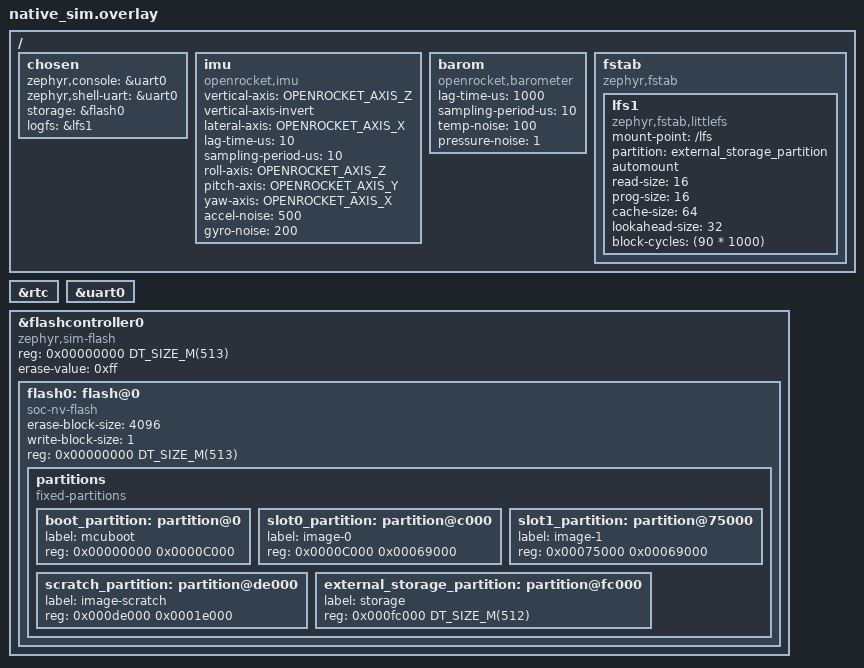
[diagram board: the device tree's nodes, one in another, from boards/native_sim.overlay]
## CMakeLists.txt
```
cmake_minimum_required(VERSION 3.20.0)

find_package(Zephyr REQUIRED HINTS $ENV{ZEPHYR_BASE})
project(sample_logging LANGUAGES C CXX)

FILE(GLOB app_sources src/*.cpp src/*.c)

#target_compile_options(app PRIVATE -Wno-unused-parameter -Wno-unused-function -Wno-ignored-qualifiers)
target_sources(app PRIVATE ${app_sources})
```

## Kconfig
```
# Copyright (c) 2021 Nordic Semiconductor ASA
# SPDX-License-Identifier: Apache-2.0
#
# This file is the application Kconfig entry point. All application Kconfig
# options can be defined here or included via other application Kconfig files.
# You can browse these options using the west targets menuconfig (terminal) or
# guiconfig (GUI).

menu "Zephyr"
source "Kconfig.zephyr"
endmenu


module = APP_PHASE_DETECT
module-str = APP_PHASE_DETECT
source "subsys/logging/Kconfig.template.log_config"
```

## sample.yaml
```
sample:
  description: phase-detection
  name: phase-detection
common:
  build_only: true
  platform_allow:
    - native_sim
tests:
  samples.phase_detection.default: {}
```

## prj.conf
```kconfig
# CPP
CONFIG_CPP=y
CONFIG_REQUIRES_FULL_LIBCPP=y
CONFIG_STD_CPP20=y
CONFIG_ASAN=y

CONFIG_F_CORE=y
CONFIG_F_CORE_SENSOR=y
CONFIG_F_CORE_OS=y
CONFIG_F_CORE_UTILS=y

CONFIG_SENSOR=y
CONFIG_SHELL=y
CONFIG_SENSOR_SHELL=y
CONFIG_FILE_SYSTEM_SHELL=y
CONFIG_HEAP_MEM_POOL_SIZE=4096
CONFIG_EVENTS=y


CONFIG_SERIAL=y
CONFIG_CBPRINTF_FP_SUPPORT=y
CONFIG_CONSOLE=y

CONFIG_LOG=y
CONFIG_LOG_MODE_IMMEDIATE=y
CONFIG_APP_PHASE_DETECT_LOG_LEVEL_DBG=y

# Flash chip is SPI
CONFIG_FLASH=y
# LittleFS requires a flash map device
CONFIG_FLASH_MAP=y
CONFIG_FLASH_PAGE_LAYOUT=y

# Use filesystem
CONFIG_FILE_SYSTEM=y
# Use LittleFS as the filesystem
CONFIG_FILE_SYSTEM_LITTLEFS=y
# LittleFS is mounted on a flash map device
CONFIG_FS_LITTLEFS_FMP_DEV=y 

# Flash chip is SPI
CONFIG_FLASH=y
# LittleFS requires a flash map device
CONFIG_FLASH_MAP=y
CONFIG_FLASH_PAGE_LAYOUT=y

# CONFIG_FUSE_FS_ACCESS=y
```

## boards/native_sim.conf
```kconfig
CONFIG_SYS_CLOCK_TICKS_PER_SEC=10000
CONFIG_UBSAN=y

CONFIG_OPENROCKET_SENSORS=y

CONFIG_OPENROCKET_NOISE=y
CONFIG_OPENROCKET_NOISE_SEED=0
CONFIG_TEST_RANDOM_GENERATOR=y
CONFIG_XOSHIRO_RANDOM_GENERATOR=y
CONFIG_TIMER_RANDOM_GENERATOR=y

CONFIG_OPENROCKET_DATA_FILE="../../../data/orksim_csv/omen.csv"
CONFIG_OPENROCKET_MS_BEFORE_LAUNCH=2000
CONFIG_OPENROCKET_SCALAR_TYPE_DOUBLE=y
CONFIG_OPENROCKET_EVENT_LOG=y

CONFIG_OPENROCKET_IMU=y
CONFIG_OPENROCKET_BAROMETER=y
```

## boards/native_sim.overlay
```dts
/ {
    chosen {
        zephyr,console = &uart0;
        zephyr,shell-uart = &uart0;

        storage = &flash0;
        logfs = &lfs1;
    };


    imu: imu {
        status = "okay";
        // broken;
        compatible = "openrocket,imu";
        vertical-axis = "OPENROCKET_AXIS_Z";
        vertical-axis-invert;
        lateral-axis = "OPENROCKET_AXIS_X";
        lag-time-us = <10>;
        sampling-period-us = <10>;

        roll-axis = "OPENROCKET_AXIS_Z";
        pitch-axis = "OPENROCKET_AXIS_Y";
        yaw-axis = "OPENROCKET_AXIS_X";

        accel-noise = <500>;
        gyro-noise = <200>;
    };

    barom: barom {
        status = "okay";
        compatible = "openrocket,barometer";
        lag-time-us = <1000>;
        sampling-period-us = <10>;
        temp-noise = <100>; // millicelsius
        pressure-noise = <1>; // kPa / 1000
    };

    fstab {
        compatible = "zephyr,fstab";
        lfs1: lfs1 {
            compatible = "zephyr,fstab,littlefs";
            mount-point = "/lfs";
            partition = <&external_storage_partition>;
            automount;

            // the binding reccomends defaults for these
            read-size = <16>;
            prog-size = <16>;
            cache-size = <64>; // may need to grow for optimization
            lookahead-size = <32>;
            block-cycles = <(90 * 1000)>;
            // the datasheet gives 100K P-E cycles
            // NOTE: this seems to default to 512 for the mounted filesystem
            // anyway
        };
    };

};
&rtc {
    status = "okay";
};
&uart0 {
    status = "okay";
};

&flashcontroller0 {
    status = "okay";
    compatible = "zephyr,sim-flash";
    reg = <0x00000000 DT_SIZE_M(513)>;

    #address-cells = <1>;
    #size-cells = <1>;
    erase-value = <0xff>;

    flash0: flash@0 {
        status = "okay";
        compatible = "soc-nv-flash";
        erase-block-size = <4096>;
        write-block-size = <1>;
        reg = <0x00000000 DT_SIZE_M(513)>; // builtin stuff + external flash simulation

        partitions {
            compatible = "fixed-partitions";
            #address-cells = <1>;
            #size-cells = <1>;

            boot_partition: partition@0 {
                label = "mcuboot";
                reg = <0x00000000 0x0000C000>;
            };
            slot0_partition: partition@c000 {
                label = "image-0";
                reg = <0x0000C000 0x00069000>;
            };
            slot1_partition: partition@75000 {
                label = "image-1";
                reg = <0x00075000 0x00069000>;
            };
            scratch_partition: partition@de000 {
                label = "image-scratch";
                reg = <0x000de000 0x0001e000>;
            };
            external_storage_partition: partition@fc000 {
                label = "storage";
                reg = <0x000fc000 DT_SIZE_M(512)>;
            };
        };
    };
};
```

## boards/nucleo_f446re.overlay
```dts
/ {
    chosen {
        zephyr,console = &usart2;
    };
    imu: imu {
        compatible = "openrocket,imu";
        vertical-axis = "OPENROCKET_AXIS_Z";
        vertical-axis-invert;
        lateral-axis = "OPENROCKET_AXIS_X";
        lag-time-us = <1000>;
        sampling-period-us = <10>;

        roll-axis = "OPENROCKET_AXIS_Z";
        pitch-axis = "OPENROCKET_AXIS_Y";
        yaw-axis = "OPENROCKET_AXIS_X";
    };

    barom: barom {
        status = "okay";
        compatible = "openrocket,barometer";
        lag-time-us = <1000>;
        sampling-period-us = <10>;

    };

    gnss: gnss{
        status = "okay";
        compatible = "openrocket,gnss";
        lag-time-us = <1000>;
        sampling-period-us = <(5*1000*1000)>;
        rtc = <&rtc>;
    };
};
```

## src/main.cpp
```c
// F-Core Includes
#include "f_core/os/flight_log.hpp"
#include "f_core/utils/debouncer.hpp"
#include "f_core/utils/linear_fit.hpp"
#include "flight.h"

#include <array>
#include <f_core/device/sensor/c_accelerometer.h>
#include <f_core/device/sensor/c_barometer.h>
#include <f_core/device/sensor/c_gyroscope.h>
#include <f_core/device/sensor/c_magnetometer.h>
#include <math.h>
// Zephyr Includes
#include <zephyr/device.h>
#include <zephyr/devicetree.h>
#include <zephyr/drivers/sensor.h>
#include <zephyr/kernel.h>
#include <zephyr/logging/log.h>
LOG_MODULE_REGISTER(main, CONFIG_APP_PHASE_DETECT_LOG_LEVEL);

K_TIMER_DEFINE(imu_timer, NULL, NULL);
K_TIMER_DEFINE(barom_timer, NULL, NULL);

void imu_thread_f(void *vp_controller, void *, void *) {
    Controller &controller = *(Controller *) vp_controller;

    // > 5G-ish for a quarter second
    constexpr uint32_t boost_time_ms = 250;
    constexpr double boost_threshold_mps2 = 50;

    // < 3.5G-ish for a quarter second
    // weird since this example is doing what grim did and doing it based on magnitude not a specific axis
    // Deceleration is still acceleration which is why we cant just say < 1G
    constexpr uint32_t coast_time_ms = 250;
    constexpr double coast_threshold_mps2 = 35;
    CDebouncer<ThresholdDirection::Over, double> boost_detector{boost_time_ms, boost_threshold_mps2};
    CDebouncer<ThresholdDirection::Under, double> coast_detector{coast_time_ms, coast_threshold_mps2};

    CAccelerometer acc(*DEVICE_DT_GET_ONE(openrocket_imu));
    if (!acc.IsReady()) {
        LOG_WRN("Accelerometer not ready");
    }
    controller.SubmitEvent(Sources::IMU1, Events::PadReady);
    controller.WaitUntilEvent(Events::PadReady);

    while (!controller.HasEventOccurred(Events::GroundHit)) {
        k_timer_status_sync(&imu_timer);
        uint32_t timestamp = k_uptime_get();

        if (!acc.UpdateSensorValue()) {
            LOG_ERR("Failure reading imu");
        }
        double x = acc.GetSensorValueDouble(SENSOR_CHAN_ACCEL_X);
        double y = acc.GetSensorValueDouble(SENSOR_CHAN_ACCEL_Y);
        double z = acc.GetSensorValueDouble(SENSOR_CHAN_ACCEL_Z);
        double mag = sqrt((x * x) + (y * y) + (z * z));

        // Boost Detecting
        if (!controller.HasEventOccurred(Events::Boost)) {
            boost_detector.Feed(timestamp, mag);
            coast_detector.Feed(timestamp, mag);
            if (boost_detector.Passed()) {
                controller.SubmitEvent(Sources::IMU1, Events::Boost);
            }
        } else if (!controller.HasEventOccurred(Events::Coast)) {
            coast_detector.Feed(timestamp, mag);
            if (coast_detector.Passed()) {
                controller.SubmitEvent(Sources::IMU1, Events::Coast);
            }
        }
    }
}

using SampleType = LinearFitSample<double>;
static constexpr std::size_t window_size = 10;
using SummerType = CRollingSum<SampleType, window_size>;

struct Line {
    double m;
    double b;
    constexpr bool operator==(const Line &rhs) const { return m == rhs.m && b == rhs.b; }
};

// Value returned when we don't have enough information to fit a line
constexpr Line bad_line{0, 0};

Line find_line(const SummerType &summer) {
    std::size_t N = summer.Size();
    SampleType E = summer.Sum();
    double denom = (N * E.xx - E.x * E.x);
    if (denom == 0) {
        // Would have divided by 0
        return bad_line;
    }
    double m = (N * E.xy - E.x * E.y) / denom;
    double b = (E.y - m * E.x) / N;
    return Line{m, b};
}

double rrc3_altitude_conversion_to_feet(double P_sta_kpa) {
    // Constants from https://www.weather.gov/media/epz/wxcalc/pressureAltitude.pdf
    static constexpr double standard_atmosphere_exponent = 0.190284;
    static constexpr double standard_atmosphere_factor = 145366.45;

    static constexpr double kpa_to_mbar = 10.0;
    static constexpr double sea_level_pressure_mbar = 1013.25;
    double P_sta_mbar = P_sta_kpa * kpa_to_mbar;

    return (1 - pow(P_sta_mbar / sea_level_pressure_mbar, standard_atmosphere_exponent)) * standard_atmosphere_factor;
}

using BoostDebouncerT = CDebouncer<ThresholdDirection::Over, double>;
using NoseoverDebouncerT = CDebouncer<ThresholdDirection::Under, double>;
using MainHeightDebouncerT = CDebouncer<ThresholdDirection::Under, double>;
using NoVelocityDebouncerT = CDebouncer<ThresholdDirection::Under, double>;

void barom_thread_f(void *vp_controller, void *, void *) {
    Controller &controller = *(Controller *) vp_controller;

    CBarometer barometer(*DEVICE_DT_GET_ONE(openrocket_barometer));
    if (!barometer.IsReady()) {
        LOG_WRN("Accelerometer not ready");
    }
    controller.SubmitEvent(Sources::Barom1, Events::PadReady);
    controller.WaitUntilEvent(Events::PadReady);

    // Measure
    barometer.UpdateSensorValue();
    double init_press_kpa = barometer.GetSensorValueDouble(SENSOR_CHAN_PRESS);
    double init_feet_asl = rrc3_altitude_conversion_to_feet(init_press_kpa);
    double max_feet_agl = 0;

    SummerType velocity_summer{SampleType{0, 0}};
    CMovingAverage<double, 100> ground_level_avger{init_feet_asl};

    // >5g for 2 seconds
    constexpr uint32_t boost_time_ms = 2000; // ms
    constexpr uint32_t boost_threshold = 5;  // ft/s
    BoostDebouncerT boost_debouncer{boost_time_ms, boost_threshold};

    // Under 0ft/s for 0.5 seconds
    constexpr uint32_t noseover_velocity_time_ms = 500;
    constexpr double noseover_velocity_threshold = 0.0;
    NoseoverDebouncerT noseover_debouncer{noseover_velocity_time_ms, noseover_velocity_threshold};

    // Under 500ft for 0.5 seconds
    constexpr uint32_t mainheight_time_ms = 500;
    constexpr double mainheight_threshold = 500.0;
    MainHeightDebouncerT mainheight_debouncer{mainheight_time_ms, mainheight_threshold};

    // under 10 ft/s for 10 seconds
    constexpr uint32_t no_vel_time_ms = 10 * 1000;
    constexpr double no_vel_threshold = 10.0;
    NoVelocityDebouncerT no_vel_debouncer{no_vel_time_ms, no_vel_threshold};

    while (!controller.HasEventOccurred(Events::GroundHit)) {
        k_timer_status_sync(&barom_timer);
        bool good = barometer.UpdateSensorValue();
        if (!good) {
            LOG_ERR("Failure reading barometer");
        }

        // Measure
        double press_kpa = barometer.GetSensorValueDouble(SENSOR_CHAN_PRESS);

        uint32_t time_ms = k_uptime_get();
        double time_s = (double) (time_ms) / 1000.0;

        // Calculate
        double feet = rrc3_altitude_conversion_to_feet(press_kpa);

        velocity_summer.Feed({time_s, feet});
        Line line = find_line(velocity_summer);

        // Not enough samples, don't check
        if (line == bad_line) {
            continue;
        }
        double velocity_ft_s = line.m;
        double feet_agl = feet - ground_level_avger.Avg();
        if (feet_agl > max_feet_agl) {
            max_feet_agl = feet_agl;
        }
        // Check
        if (!controller.HasEventOccurred(Events::Boost)) {
            ground_level_avger.Feed(feet);
            boost_debouncer.Feed(time_ms, velocity_ft_s);
            if (boost_debouncer.Passed()) {
                controller.SubmitEvent(Sources::Barom1, Events::Boost);
            }
        }
        if (!controller.HasEventOccurred(Events::Noseover)) {
            noseover_debouncer.Feed(time_ms, velocity_ft_s);
            if (controller.HasEventOccurred(Events::Boost) && noseover_debouncer.Passed()) {
                controller.SubmitEvent(Sources::Barom1, Events::Noseover);
                LOG_INF("Noseover occured at barometeric altitude of %.2f ft agl (%.2f ft asl)", feet_agl, feet);
            }
        }

        if (!controller.HasEventOccurred(Events::MainChute)) {
            mainheight_debouncer.Feed(time_ms, feet_agl);
            if (controller.HasEventOccurred(Events::Noseover) && mainheight_debouncer.Passed()) {
                controller.SubmitEvent(Sources::Barom1, Events::MainChute);
            }
        }
        if (!controller.HasEventOccurred(Events::GroundHit)) {
            no_vel_debouncer.Feed(time_ms, fabs(velocity_ft_s));
            if (controller.HasEventOccurred(Events::Boost) && no_vel_debouncer.Passed()) {
                controller.SubmitEvent(Sources::Barom1, Events::GroundHit);
            }
        }
    }
    LOG_INF("Maximum barometric altitude of %.2f ft agl", max_feet_agl);
}

K_THREAD_STACK_DEFINE(imu_thread_stack_area, 1024);
struct k_thread imu_thread_data;

K_THREAD_STACK_DEFINE(barom_thread_stack_area, 1024);
struct k_thread barom_thread_data;
CFlightLog fl{"/lfs/flight_log.txt"};

void event_handler(Controller::EventNotification event) {
    int64_t ms = k_ticks_to_ms_near32(event.uptimeTicks);
    static constexpr size_t buf_size = 64;
    char buf[buf_size] = {0};
    if (event.type == Controller::EventType::EventOccured) {
        snprintf(buf, buf_size, "%s occured %s.", eventNames[event.event],
                 event.hasAlreadyOccured ? "(but already occured)" : "");
        LOG_INF("%s", buf);
        fl.Write(ms, buf);
    } else {
        snprintf(buf, buf_size, "%s submitted by %s.", eventNames[event.event], sourceNames[event.source]);
        LOG_INF("%s", buf);
        fl.Write(ms, buf);
    }
}

int main() {
    Controller controller{sourceNames, eventNames, timerEvents, deciders, event_handler};

    k_thread_create(&barom_thread_data, barom_thread_stack_area, K_THREAD_STACK_SIZEOF(barom_thread_stack_area),
                    barom_thread_f, &controller, NULL, NULL, 0, 0, K_NO_WAIT);

    k_thread_create(&imu_thread_data, imu_thread_stack_area, K_THREAD_STACK_SIZEOF(imu_thread_stack_area), imu_thread_f,
                    &controller, NULL, NULL, 0, 0, K_NO_WAIT);
    k_timer_stop(&imu_timer);
    k_timer_stop(&barom_timer);

    LOG_DBG("Waiting until everyone ready");

    controller.WaitUntilEvent(Events::PadReady);
    LOG_DBG("System ready:\tstart boost detecting");

    // Start sensing
    k_timer_start(&imu_timer, K_MSEC(1), K_MSEC(1));
    k_timer_start(&barom_timer, K_MSEC(10), K_MSEC(10));

    LOG_DBG("Waiting for boost");
    controller.WaitUntilEvent(Events::Boost);
    LOG_DBG("Boost detected:\ttell your friends (engineering cams)");

    LOG_DBG("Waiting for coast");
    controller.WaitUntilEvent(Events::Coast);
    LOG_DBG("Coast detected:\tturn down IMU data rate");

    // IMU can chill out after all the cool stuff happens
    k_timer_start(&imu_timer, K_MSEC(10), K_MSEC(10));

    LOG_DBG("Waiting for noseover");
    controller.WaitUntilEvent(Events::Noseover);
    LOG_DBG("Noseover detected:\tdeploy charges");

    LOG_DBG("Waiting for main");
    controller.WaitUntilEvent(Events::MainChute);
    LOG_DBG("Main Chute Deploy:\tdeploy more charges");

    LOG_DBG("Waiting for ground");
    controller.WaitUntilEvent(Events::GroundHit);
    LOG_DBG("Hit The ground:\tStop recording data");

    // Stop recording
    k_timer_stop(&imu_timer);
    k_timer_stop(&barom_timer);

    controller.WaitUntilEvent(Events::CamerasOff);
    LOG_DBG("Flight over:\tTurn off cameras");

    fl.Sync();
    LOG_INF("Closed flight log");
    return 0;
}
```

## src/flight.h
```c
#pragma once
#include <array>
#include <cstdint>
#include <f_core/flight/c_phase_controller.h>

/**
 * Flight Events for a fictional flight
 */
enum Events : uint8_t { PadReady, Boost, Coast, Noseover, MainChute, GroundHit, CamerasOff, NumEvents };
inline constexpr std::array<const char *, Events::NumEvents> eventNames = {
    "PadReady", "Boost", "Coast", "Noseover", "MainChute", "GroundHit", "CamerasOff",
};

/**
 * Sources of flight events
 */
enum Sources : uint8_t {
    IMU1,
    Barom1,
    NoseoverLockout,
    Boost2CoastTimer,
    Noseover2MainTimer,
    FullFlightTimer,
    ExtraCameraTimer,
    NumSources
};
inline constexpr std::array<const char *, Sources::NumSources> sourceNames = {
    "IMU 1 (LSM6DSL)",     "Barom 1 (BME280)",  "Noseover Lockout",  "Boost2Coast Timer",
    "Noseover2Main Timer", "Full Flight Timer", "ExtraCamera Timer",
};

inline constexpr std::size_t num_timer_events = 5;
using Controller = CPhaseController<Events, Events::NumEvents, Sources, Sources::NumSources, num_timer_events>;

/**
 * Special events triggered not by sensors but by timers between phases
 */
inline std::array<Controller::TimerEvent, num_timer_events> timerEvents = {
    // The engine should burn for around X seconds. don't detect coast unless the engine has been firing for a bit
    // Can be implemented as a lockout or as another way of progressing states if you don't want to do unboost detection
    Controller::TimerEvent{
        .start = Events::Boost,
        .event = Events::Coast,
        .time = K_SECONDS(3),
        .source = Sources::Boost2CoastTimer,
    },
    // We dont want to accidentally detect noseover when still burning or while going really fast.
    // Adds a lockout timer so even if our sensors say we nosed over, don't trust them until we've had time to slowdown
    Controller::TimerEvent{
        .start = Events::Boost,
        .event = Events::Noseover,
        .time = K_SECONDS(10),
        .source = Sources::NoseoverLockout,
    },
    // Rather than deploying chutes at an altitude, deploy them at a certain time after noseover
    Controller::TimerEvent{
        .start = Events::Noseover,
        .event = Events::MainChute,
        .time = K_SECONDS(175),
        .source = Sources::Noseover2MainTimer,
    },
    // We know our entire flight will not last longer than X seconds even if we main at apogee.
    //This stops us from overwriting flight data if we don't detect the end
    Controller::TimerEvent{
        .start = Events::Boost,
        .event = Events::GroundHit,
        .time = K_SECONDS(350),
        .source = Sources::FullFlightTimer,
    },
    // After we hit the ground, keep the cameras going for a while longer so they start a new video file and when we cut the power, no actual flight footage is lost
    Controller::TimerEvent{
        .start = Events::GroundHit,
        .event = Events::CamerasOff,
        .time = K_SECONDS(2),
        .source = Sources::ExtraCameraTimer,
    },
};

/**
 * Functions for merging the different sources of events
 * 
 * silly immediately invoked lambda because c++ doesn't support designated array initializers :(
 * still constexpr tho which is nice
 */
inline constexpr std::array<Controller::DecisionFunc, Events::NumEvents> deciders = [] {
    std::array<Controller::DecisionFunc, Events::NumEvents> arr = {nullptr};
    // Ready to go
    arr[Events::PadReady] = [](Controller::SourceStates states) -> bool {
        return states[Sources::IMU1] && states[Sources::Barom1];
    };

    // Boosting
    arr[Events::Boost] = [](Controller::SourceStates states) -> bool {
        return (states[Sources::IMU1] || states[Sources::Barom1]);
    };

    // Coasting
    arr[Events::Coast] = [](Controller::SourceStates states) -> bool {
        return states[Sources::Boost2CoastTimer] || states[Sources::IMU1];
    };

    // Noseover
    arr[Events::Noseover] = [](Controller::SourceStates states) -> bool {
        return states[Sources::NoseoverLockout] && states[Sources::Barom1];
    };

    // Main
    arr[Events::MainChute] = [](Controller::SourceStates states) -> bool {
        return states[Sources::Barom1] || states[Sources::Noseover2MainTimer];
    };

    // On the ground
    arr[Events::GroundHit] = [](Controller::SourceStates states) -> bool {
        return states[Sources::Barom1] || states[Sources::FullFlightTimer];
    };

    // After finishing stuff up (what grim did to make sure camera SD cards fully saved)
    arr[Events::CamerasOff] = [](Controller::SourceStates states) -> bool { return states[Sources::ExtraCameraTimer]; };

    return arr;
}();
```

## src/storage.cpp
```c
#include "flight.h"

#include <zephyr/kernel.h>

// void do_storage() { printk("stage %d\n", (int) Events::Noseover); }
```
